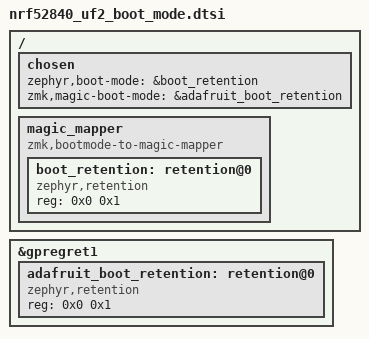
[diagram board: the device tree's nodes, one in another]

&gpregret1 {
    adafruit_boot_retention: retention@0 {
        compatible = "zephyr,retention";
        status = "okay";
        reg = <0x0 0x1>;
    };
};

/ {
    chosen {
        zephyr,boot-mode = &boot_retention;
        zmk,magic-boot-mode = &adafruit_boot_retention;
    };

    magic_mapper {
        compatible = "zmk,bootmode-to-magic-mapper";
        status = "okay";

        #address-cells = <1>;
        #size-cells = <1>;

        boot_retention: retention@0 {
            compatible = "zephyr,retention";
            status = "okay";
            reg = <0x0 0x1>;
        };
    };
};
